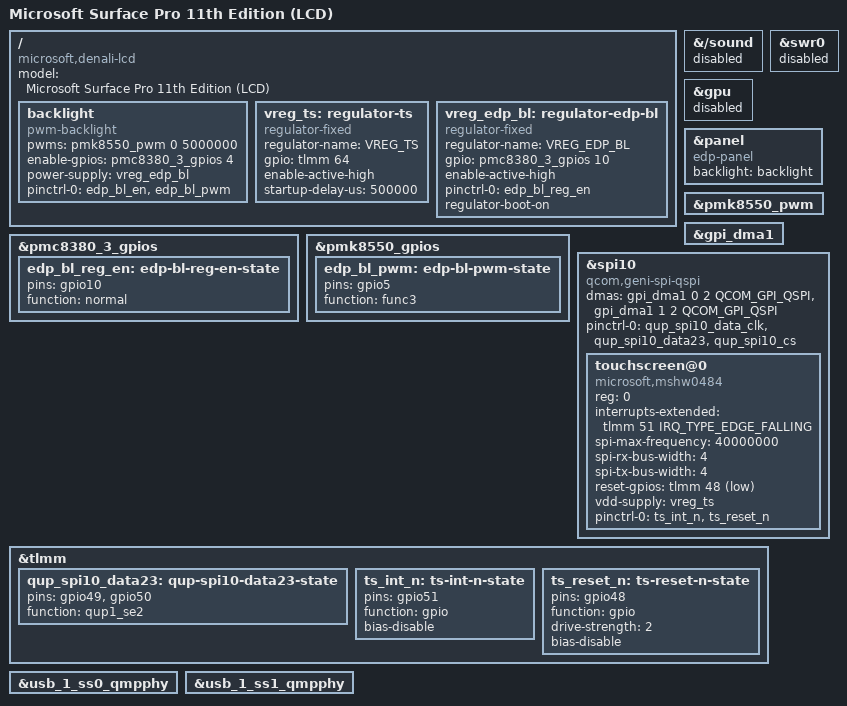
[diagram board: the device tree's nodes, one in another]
// SPDX-License-Identifier: BSD-3-Clause
/*
 * Copyright (c) 2025 Dale Whinham <daleyo@gmail.com>
 */

/dts-v1/;

#include <dt-bindings/dma/qcom-gpi.h>

#include "hamoa.dtsi"
#include "x1-microsoft-denali.dtsi"

&{/sound} {
	status = "disabled";
};

&swr0 {
	status = "disabled";
};

&gpu {
	status = "disabled";
};

/ {
	model = "Microsoft Surface Pro 11th Edition (LCD)";
	compatible = "microsoft,denali-lcd", "microsoft,denali",
		     "qcom,x1p64100", "qcom,x1e80100";

	backlight: backlight {
		compatible = "pwm-backlight";
		pwms = <&pmk8550_pwm 0 5000000>;
		enable-gpios = <&pmc8380_3_gpios 4 GPIO_ACTIVE_HIGH>;
		power-supply = <&vreg_edp_bl>;

		pinctrl-0 = <&edp_bl_en>, <&edp_bl_pwm>;
		pinctrl-names = "default";
	};

	vreg_ts: regulator-ts {
		compatible = "regulator-fixed";
		regulator-name = "VREG_TS";
		gpio = <&tlmm 64 GPIO_ACTIVE_HIGH>;
		enable-active-high;
		startup-delay-us = <500000>;
	};

	vreg_edp_bl: regulator-edp-bl {
		compatible = "regulator-fixed";

		regulator-name = "VREG_EDP_BL";

		gpio = <&pmc8380_3_gpios 10 GPIO_ACTIVE_HIGH>;
		enable-active-high;

		pinctrl-0 = <&edp_bl_reg_en>;
		pinctrl-names = "default";

		regulator-boot-on;
	};
};

&panel {
	compatible = "edp-panel";
	backlight = <&backlight>;
};

&pmc8380_3_gpios {
	edp_bl_reg_en: edp-bl-reg-en-state {
		pins = "gpio10";
		function = "normal";
	};
};

&pmk8550_gpios {
	edp_bl_pwm: edp-bl-pwm-state {
		pins = "gpio5";
		function = "func3";
	};
};

&pmk8550_pwm {
	status = "okay";
};

&gpi_dma1 {
	status = "okay";
};

&spi10 {
	compatible = "qcom,geni-spi-qspi";
	dmas = <&gpi_dma1 0 2 QCOM_GPI_QSPI>,
	       <&gpi_dma1 1 2 QCOM_GPI_QSPI>;
	pinctrl-0 = <&qup_spi10_data_clk>, <&qup_spi10_data23>, <&qup_spi10_cs>;
	status = "okay";

	touchscreen@0 {
		compatible = "microsoft,mshw0484";
		reg = <0>;
		interrupts-extended = <&tlmm 51 IRQ_TYPE_EDGE_FALLING>;
		spi-max-frequency = <40000000>;
		spi-rx-bus-width = <4>;
		spi-tx-bus-width = <4>;
		reset-gpios = <&tlmm 48 GPIO_ACTIVE_LOW>;
		vdd-supply = <&vreg_ts>;
		pinctrl-0 = <&ts_int_n>, <&ts_reset_n>;
		pinctrl-names = "default";
	};
};

&tlmm {
	qup_spi10_data23: qup-spi10-data23-state {
		pins = "gpio49", "gpio50";
		function = "qup1_se2";
	};

	ts_int_n: ts-int-n-state {
		pins = "gpio51";
		function = "gpio";
		bias-disable;
	};

	ts_reset_n: ts-reset-n-state {
		pins = "gpio48";
		function = "gpio";
		drive-strength = <2>;
		bias-disable;
	};
};

/*
 * The PS8830 retimers already carry the orientation switch of each port and,
 * through ps883x_sw_set(), forward every orientation change to the QMP combo
 * PHY behind them. Do not register the PHYs as orientation switches: they keep
 * the fixed normal lane mapping and only the retimers flip. Experiment for
 * reverse-orientation SuperSpeed; the PHYs stay registered as mode switches.
 */
&usb_1_ss0_qmpphy {
	/delete-property/ orientation-switch;
};

&usb_1_ss1_qmpphy {
	/delete-property/ orientation-switch;
};
